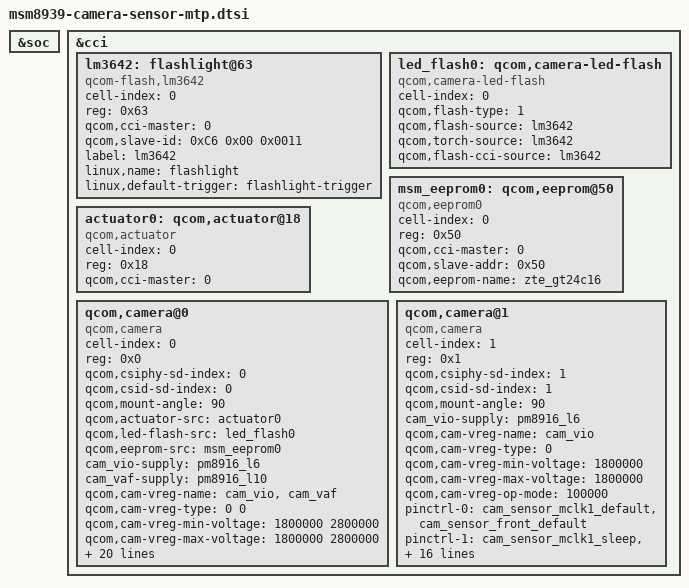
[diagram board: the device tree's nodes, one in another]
/*
 * Copyright (c) 2014-2015, The Linux Foundation. All rights reserved.
 *
 * This program is free software; you can redistribute it and/or modify
 * it under the terms of the GNU General Public License version 2 and
 * only version 2 as published by the Free Software Foundation.
 *
 * This program is distributed in the hope that it will be useful,
 * but WITHOUT ANY WARRANTY; without even the implied warranty of
 * MERCHANTABILITY or FITNESS FOR A PARTICULAR PURPOSE.  See the
 * GNU General Public License for more details.
 */

&soc {
};

&cci {
	lm3642: flashlight@63 {
		cell-index = <0>;
		reg = <0x63>;
		compatible = "qcom-flash,lm3642";
		status = "okay";
		qcom,cci-master = <0>;
		qcom,slave-id = <0xC6 0x00 0x0011>;
		label = "lm3642";
		/*qcom,gpio-no-mux = <0>;
		qcom,enable_pinctrl;
		pinctrl-names = "cam_flash_default", "cam_flash_suspend";
		pinctrl-0 = <&cam_sensor_flash_default>;
		pinctrl-1 = <&cam_sensor_flash_sleep>;
		gpios = <&msm_gpio 32 0>, <&msm_gpio 86 0>;
		qcom,gpio-flash-en = <0>;
		qcom,gpio-req-tbl-num = <0 1>;
		qcom,gpio-req-tbl-flags = <0 0>;
		qcom,gpio-req-tbl-label = "FLASH_EN", "FLASH_NOW";
		qcom,gpio-flash-now = <1>;*/
		linux,name = "flashlight";
		linux,default-trigger = "flashlight-trigger";
	};

	led_flash0: qcom,camera-led-flash {
		cell-index = <0>;
		compatible = "qcom,camera-led-flash";
		qcom,flash-type = <1>;
		qcom,flash-source = <&lm3642>;
		qcom,torch-source = <&lm3642>;
		qcom,flash-cci-source = <&lm3642>;
	};

//ZTE yuxin add for P839F30 rear cam IMX214 2014.11.05 ++
  //eeprom:
  msm_eeprom0: qcom,eeprom@50 {
		cell-index = <0>;
		reg = <0x50>;
		compatible = "qcom,eeprom0";
		qcom,cci-master = <0>;
		qcom,slave-addr = <0x50>;
		qcom,eeprom-name = "zte_gt24c16";
	};

  //actuator:
	actuator0: qcom,actuator@18 {
		cell-index = <0>;
		reg = <0x18>;
		compatible = "qcom,actuator";
		qcom,cci-master = <0>;
	};
	
	//rear cam sensor:
	qcom,camera@0 {
		cell-index = <0>;
		compatible = "qcom,camera";
		reg = <0x0>;
		qcom,csiphy-sd-index = <0>;
		qcom,csid-sd-index = <0>;
		qcom,mount-angle = <90>;
		qcom,actuator-src = <&actuator0>;
		qcom,led-flash-src = <&led_flash0>;
		qcom,eeprom-src = <&msm_eeprom0>;
		cam_vio-supply = <&pm8916_l6>;
		cam_vaf-supply = <&pm8916_l10>;
		qcom,cam-vreg-name = "cam_vio", "cam_vaf";
		qcom,cam-vreg-type = < 0 0>;
		qcom,cam-vreg-min-voltage = <1800000 2800000>;
		qcom,cam-vreg-max-voltage = <1800000 2800000>;
		qcom,cam-vreg-op-mode = <100000  100000>;
		pinctrl-names = "cam_default", "cam_suspend";
		pinctrl-0 = <&cam_sensor_mclk0_default &cam_sensor_rear_default>;
		pinctrl-1 = <&cam_sensor_mclk0_sleep &cam_sensor_rear_sleep>;
		gpios = <&msm_gpio 26 0>,
			<&msm_gpio 35 0>,
			<&msm_gpio 109 0>,
			<&msm_gpio 69 0>;
		qcom,gpio-reset = <1>;
		qcom,gpio-vdig = <2>;
		qcom,gpio-vana = <3>;
		qcom,gpio-req-tbl-num = <0 1 2 3>;
		qcom,gpio-req-tbl-flags = <1 0 0 0>;
		qcom,gpio-req-tbl-label = "CAMIF_MCLK0",
			"CAM_RESET1",
			"SENSOR_GPIO_VDIG",
			"SENSOR_GPIO_VANA";
		qcom,sensor-position = <0>;
		qcom,sensor-mode = <0>;
		qcom,cci-master = <0>;
		status = "ok";
		clocks = <&clock_gcc clk_mclk0_clk_src>,
				<&clock_gcc clk_gcc_camss_mclk0_clk>;
		clock-names = "cam_src_clk", "cam_clk";
	};
//ZTE yuxin add for P839F30 rear cam IMX214 2014.11.05 --

 /**********ZTE,modify by gaoyangyang for P839F30/s5k5e2 20141104++++++++****************/ 
	qcom,camera@1 {
		cell-index = <1>;
		compatible = "qcom,camera";
		reg = <0x1>;
		qcom,csiphy-sd-index = <1>;
		qcom,csid-sd-index = <1>;
		qcom,mount-angle = <90>;
		cam_vio-supply = <&pm8916_l6>;
		qcom,cam-vreg-name =  "cam_vio";
		qcom,cam-vreg-type = <0>;
		qcom,cam-vreg-min-voltage = <1800000>;
		qcom,cam-vreg-max-voltage = <1800000>;
		qcom,cam-vreg-op-mode = <100000>;
		pinctrl-names = "cam_default", "cam_suspend";
		pinctrl-0 = <&cam_sensor_mclk1_default &cam_sensor_front_default>;
		pinctrl-1 = <&cam_sensor_mclk1_sleep &cam_sensor_front_sleep>;
		gpios = <&msm_gpio 27 0>,
			<&msm_gpio 28 0>,
			<&msm_gpio 17 0>,
			<&msm_gpio 69 0>;
		qcom,gpio-reset = <1>;
		qcom,gpio-vdig = <2>;
		qcom,gpio-vana = <3>;
		qcom,gpio-req-tbl-num = <0 1 2 3>;
		qcom,gpio-req-tbl-flags = <1 0 0 0>;
		qcom,gpio-req-tbl-label = "CAMIF_MCLK1",
			"CAM_RESET2",
			"SENSOR_GPIO_VDIG",
			"SENSOR_GPIO_VANA";
		qcom,sensor-position = <1>;
		qcom,sensor-mode = <0>;
		qcom,cci-master = <0>;
		status = "ok";
		clocks = <&clock_gcc clk_mclk1_clk_src>,
				<&clock_gcc clk_gcc_camss_mclk1_clk>;
		clock-names = "cam_src_clk", "cam_clk";
	};
};
/**********ZTE,modify by gaoyangyang for P839F30/s5k5e2 20141104--------****************/
